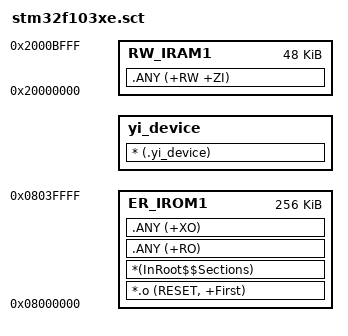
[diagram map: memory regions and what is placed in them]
; *************************************************************
; *** Scatter-Loading Description File generated by uVision ***
; *************************************************************

LR_IROM1 0x08000000 0x00040000  {    ; load region size_region
  ER_IROM1 0x08000000 0x00040000  {  ; load address = execution address
   *.o (RESET, +First)
   *(InRoot$$Sections)
   .ANY (+RO)
   .ANY (+XO)
  }

  ; Keep the device registry in its own execution region.  The linker
  ; automatically exports Image$$yi_device$$Base and $$Limit for it.
  yi_device +0 ALIGN 4 {
   * (.yi_device)
  }
  RW_IRAM1 0x20000000 0x0000C000  {  ; RW data
   .ANY (+RW +ZI)
  }
}

